# wsoc_mmu_secure register map
Vendor: Texas Instruments
Peripheral module from a debugger description file (folder CC35X1E).
Registers are 32-bit, access per field, reset 0x0 unless marked. A register's access mark holds for its fields unless they carry their own. Offsets are as the file gives them; lines under a group give offsets from that group; [hi:lo] are bit positions; {n}, {i} and the like mark numbered series; 'fields as' and 'values as' point back to an identical list; <NAME> marks a mode.

## wsoc_mmu_secure
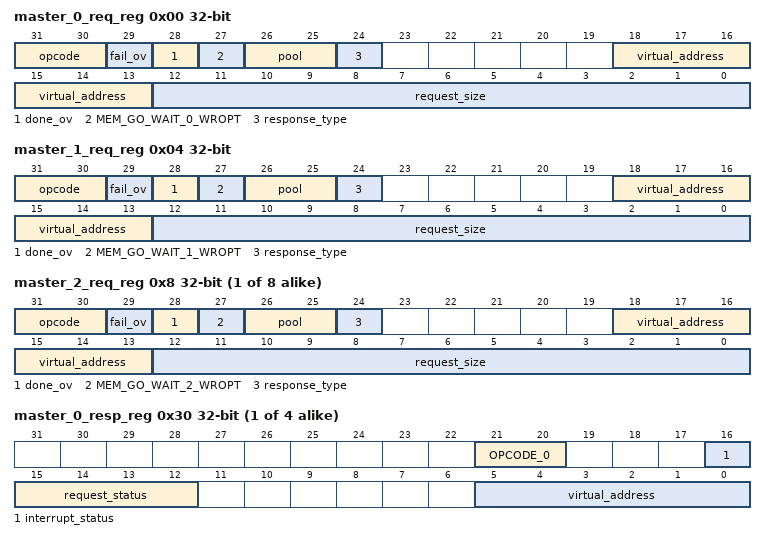
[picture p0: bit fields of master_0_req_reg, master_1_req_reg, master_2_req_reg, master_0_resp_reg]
0x00 master_0_req_reg reset not defined
  [31:30] opcode rw — Opcode : alloc (2'b00) / re-alloc (2'b01) / de-alloc (2'b10)
  [29] fail_ov rw — go to "no req" status instead of "error"
  [28] done_ov rw — go to "no req" status instead of "done"
  [27] MEM_GO_WAIT_0_WROPT rw — 1 = when fail on size or pool go to "wait" and not to "fail"/"no_req"
  [26:25] pool rw — Pool = TX (2'b00) / RX (2'b01) / management (2'b10)
  [24] response_type rw — 1 = response with interrupt
  [18:13] virtual_address rw — Virtual descriptor - should be shifted to the left to create the virtual address
  [12:0] request_size rw — Size (in Bytes) : 1-4096
0x04 master_1_req_reg reset not defined
  [31:30] opcode rw — Opcode : alloc (2'b00) / re-alloc (2'b01) / de-alloc (2'b10)
  [29] fail_ov rw — go to "no req" status instead of "error"
  [28] done_ov rw — go to "no req" status instead of "done"
  [27] MEM_GO_WAIT_1_WROPT rw — 1 = when fail on size or pool go to "wait" and not to "fail"/"no_req"
  [26:25] pool rw — Pool = TX (2'b00) / RX (2'b01) / management (2'b10)
  [24] response_type rw — 1 = response with interrupt
  [18:13] virtual_address rw — Virtual descriptor - should be shifted left to create the virtual address
  [12:0] request_size rw — Size (in Bytes) : 1-4096
{0x0+4i} master_{i}_req_reg reset not defined (i=2..9)
  [31:30] opcode rw — Opcode : alloc (2'b00) / re-alloc (2'b01) / de-alloc (2'b10)
  [29] fail_ov rw — go to "no req" status instead of "error"
  [28] done_ov rw — go to "no req" status instead of "done"
  [27] MEM_GO_WAIT_{i}_WROPT rw — 1 = when fail on size or pool go to "wait" and not to "fail"/"no_req"
  [26:25] pool rw — Pool = TX (2'b00) / RX (2'b01) / management (2'b10)
  [24] response_type rw — 1 = response with interrupt
  [18:13] virtual_address rw — Virtual descriptor - should be shifted left to create virtual address
  [12:0] request_size rw — Size (in Bytes) : 1-4096
{0x30+4i} master_{i}_resp_reg ro (i=0..3)
  [21:20] OPCODE_{i} — request opcode - updated when in "wait" status
  [16] interrupt_status — when "1" indicates that finished one iteration on the FSM and is in sticky mode
  [15:12] request_status — 4'b0000 = NO_REQ 4'b0010 = WAIT 4'b0001 = IN_PROGRESS 4'b1000 = SUCCESS 4'b1001 = FAIL_NF_DESC // NF = No Free 4'b1010 = FAIL_NF_MB // NF = No Free 4'b1011 = FAIL_SW 4'b1111 = ERROR
  [5:0] virtual_address — virtual descriptor
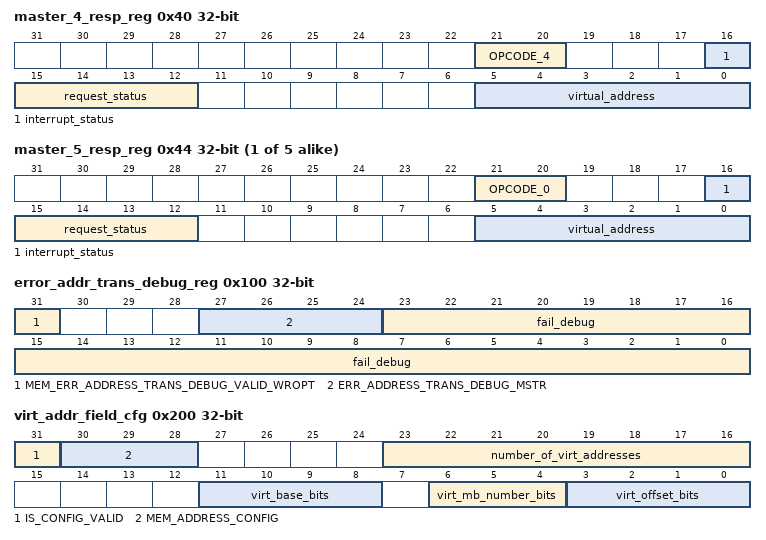
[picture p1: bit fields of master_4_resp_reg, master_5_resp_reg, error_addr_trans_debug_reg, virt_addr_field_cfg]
0x40 master_4_resp_reg ro
  [21:20] OPCODE_4 — request opcode - updated when in "wait" status
  [16] interrupt_status — when "1" indicates that finished one iteration on the FSM and is in sticky mode
  [15:12] request_status — 4'b0000 = NO_REQ 4'b0010 = WAIT 4'b0001 = IN_PROGRESS 4'b1000 = SUCCESS 4'b1001 = FAIL_NF_DESC // NF = No Free 4'b1010 = FAIL_NF_MB // NF = No Free 4'b1011 = FAIL_SW 4'b1111 = ERROR
  [5:0] virtual_address — virtual desriptor
{0x30+4i} master_{i}_resp_reg ro (i=5..9)
  fields as master_0_resp_reg
0x58 de_alloc_fifo_manager_cfg reset not defined
  [0] MEM_DEALLOC_FIFO_MANAGER_EN_WROPT rw — enables the dealloc fifo manager. when set to "1" it set to "1" shadow register, which will update the real register when fifo manager isn't during operation.
0x100 error_addr_trans_debug_reg reset not defined
  [31] MEM_ERR_ADDRESS_TRANS_DEBUG_VALID_WROPT rw — valid bit, when 1 the data is valid, and can't be written by the HW till FW clears it.
  [27:24] ERR_ADDRESS_TRANS_DEBUG_MSTR ro — The master id that triggered the address translation interrupt.
  [23:0] fail_debug ro — The address that triggered the address translation interrupt.
0x200 virt_addr_field_cfg reset not defined
  [31] IS_CONFIG_VALID ro — valid if MEM_ADDRESS_CONFIG is in range 0..7 (2 and 5 are not supporterd - 128B MMBLK mode) ADDR_CFG_0 : is_config_valid = 1'b1; ADDR_CFG_1 : is_config_valid = 1'b1; ADDR_CFG_2 : is_config_valid = 1'b0; //128B is not supported in Osprey ADDR_CFG_3 : is_config_valid = 1'b1; ADDR_CFG_4 : is_config_valid = 1'b1; ADDR_CFG_5 : is_config_valid = 1'b0; //128B is not supported in Osprey ADDR_CFG_6 : is_config_valid = 1'b1; ADDR_CFG_7 : is_config_valid = 1'b1;
  [30:28] MEM_ADDRESS_CONFIG rw — the configurations need to be correlated to the other fields - virt_offset_bits, virt_mb_number_bits and virt_base_bits config = 0 : 128 virt desc, 8 mb (max in each virt desc), 512B (each mb size) -> 4KB virtual space config = 1 : 128 virt desc, 16 mb (max in each virt desc), 256B (each mb size) -> 4KB virtual space config = 2 : 128 virt desc, 32 mb (max in each virt desc), 128B (each mb size) -> 4KB virtual space config = 3 : 256 desc, 4 mb (max in each virt desc), 512B (each mb size) -> 2KB virtual space config = 4 : 256 desc, 8 mb (max in each virt desc), 256B (each mb size) -> 2KB virtual space config =5 : 256 desc, 16 mb (max in each virt desc), 128B (each mb size) -> 2KB virtual space config = 6 : 128 virt desc, 16 mb (max in each virt desc), 512B (each mb size) -> 8KB virtual space config = 7 : 128 virt desc, 32 mb (max in each virt desc), 256B (each mb size) -> 8KB virtual space
  [23:16] number_of_virt_addresses rw — number of virtual descriptors - should be also synced with the tail pointers this value is used in the init fsm MUST BE EVEN NUMBER. odd value will fail the HW.
  [11:8] virt_base_bits ro — size in bits of virtual base field: mem_virt_base_bits[3:0] == 7, can represent 128 virt desc -> for configurations 0,1,2 mem_virt_base_bits[3:0] == 8, can represent 256 virt desc -> for configurations 3,4,5
  [6:4] virt_mb_number_bits ro — size in bits of virtual memblock number field: mem_virt_mb_number_bits[2:0] == 3'h2, can represent 4 mb -> for configuration 3 mem_virt_mb_number_bits[2:0] == 3'h3, can represent 8 mb -> for configurations 0,4 mem_virt_mb_number_bits[2:0] == 3'h4, can represent 16 mb -> for configurations 1,5 mem_virt_mb_number_bits[2:0] == 3'h5, can represent 32 mb -> for configuration 2
  [3:0] virt_offset_bits ro — size in bits of virtual offset field: mem_virt_offset_bits[3:0] == 4'h9, can represent 512B in the mb -> for configurations 0,3 mem_virt_offset_bits[3:0] == 4'h8, can represent 256B in the mb -> for configurations 1,4 mem_virt_offset_bits[3:0] == 4'h7, can represent 128B in the mb -> for configurations 2,5
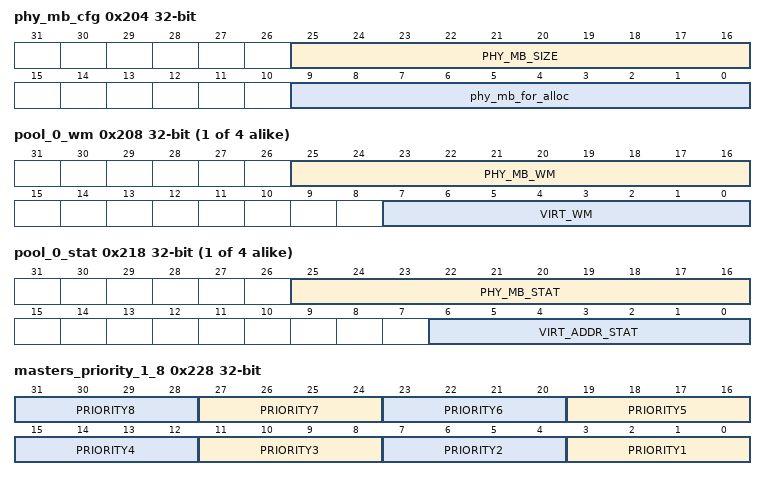
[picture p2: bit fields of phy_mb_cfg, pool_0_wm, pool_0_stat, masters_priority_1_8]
0x204 phy_mb_cfg reset not defined
  [25:16] PHY_MB_SIZE rw — physical memblock size, should be one of these options: 128, 256, 512 (the design supports 2^... format)
  [9:0] phy_mb_for_alloc rw — number of physical memblocks for allocation. should be synced with the tail pointers. this value is used in the init fsm. MUST BE EVEN NUMBER. odd value will fail the HW.
{0x208+4i} pool_{i}_wm reset not defined (i=0..3)
  [25:16] PHY_MB_WM rw — physical mb pool limit can be water mark or statistics. if water mark mechanism is enabled, when the number of virtual used (allocated) is higher than this value, this pool will fail to allocate. if statistics (stat) mechanism is enabled, when the number of virtual used (allocated) in this pool higher than this value, this pool will fail to allocate.
  [7:0] VIRT_WM rw — virtual desc pool limit can be water mark or statistics. if water mark mechanism is enabled, when the number of virtual used (allocated) is higher than this value, this pool will fail to allocate. if statistics (stat) mechanism is enabled, when the number of virtual used (allocated) in this pool higher than this value, this pool will fail to allocate.
{0x218+4i} pool_{i}_stat (i=0..3)
  [25:16] PHY_MB_STAT rw — physical memblocks statistics - how many memblocks allocated in this pool
  [6:0] VIRT_ADDR_STAT rw — virtual address statistics - how many virtual descriptors allocated in this pool
0x228 masters_priority_1_8 rw reset not defined
  [4n-1:4n-4] PRIORITY{n} (n=1..8) — master id assigned to priority {n}
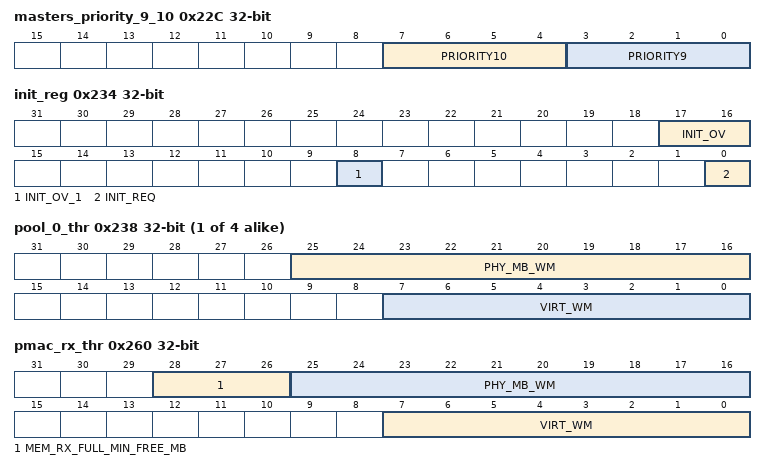
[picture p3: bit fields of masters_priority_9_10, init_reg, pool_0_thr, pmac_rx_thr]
0x22C masters_priority_9_10 reset not defined
  [7:4] PRIORITY10 rw — master id assigned to priority 10
  [3:0] PRIORITY9 rw — master id assigned to priority 9
0x230 fsms_arb_priority reset not defined
  [0] MEM_MNG_FSM rw — "0" for Address Translation FSM, "1" for Memory Management FSM
0x234 init_reg reset not defined
  [17:16] INIT_OV ro — init state 00 - INIT_IDLE 01 - INIT_RUN 10 - INIT_DONE
  [8] INIT_OV_1 ro — constant register configuration from top AOD select if MMU will run INIT after reset 0 = run INIT after reset 1 = do NOT run init
  [0] INIT_REQ rw — command to start init of MMU memories
{0x238+4i} pool_{i}_thr reset not defined (i=0..3)
  [25:16] PHY_MB_WM rw — threshold value for allocated physical memblocks. in pool water mark mechanism, when mb used number is going under this value, an interrupt will be triggered if isn't masked. in pool statistics mechanism, when this pool allocated mb number is going under this avlue, an interrupt will be triggered if not masked.
  [7:0] VIRT_WM rw — threshold value for allocated virtual descriptors. in pool water mark mechanism, when virt used descriptors number is going under this value, an interrupt will be triggered if isn't masked. in pool statistics mechanism, when this pool allocated virt descriptors number is going under this avlue, an interrupt will be triggered if not masked.
0x260 pmac_rx_thr reset not defined
  [28:26] MEM_RX_FULL_MIN_FREE_MB rw — impact rx_full indication number of free MB needed BELOW the minimum threshold between WM (mem_pool_phy_mb_wm_1) and PHY (mem_phy_mb_for_alloc) needed in order to avoid init-alloc-requests (of size > 1) that will fail because free_mb is less than requested_mb
  [25:16] PHY_MB_WM rw — threshold value for allocated physical memblocks. used by pmac_rx_adu as mmu-almost-full when MEM_POOL_STAT_MECH = 0 (pool WaterMark): set when mb_used is above this threshold value when MEM_POOL_STAT_MECH = 1 (pool Statistics): set when pool_phy_mb_addr_stat_1(rx pool) is above this threshold value
  [7:0] VIRT_WM rw — threshold value for allocated virtual descriptors. used by pmac_rx_adu as mmu-almost-full when MEM_POOL_STAT_MECH = 0 (pool WaterMark): set when virt_used is above this threshold value when MEM_POOL_STAT_MECH = 1 (pool Statistics): set when pool_virt_addr_stat_1(rx pool) is above this threshold value
0x270 message_buffer_config_1 reset not defined
  [17:0] MEM_MSG_BUF_START_ADDR rw — message_buffer start-address - OCP offset from PRAM BASE address represents the actual OCP maddr[17:0] of PRAM 16 MSBs [17:2] are used as start pointer to RAM. 2 LSBs [1:0] are dropped and assumed to be 2'b00
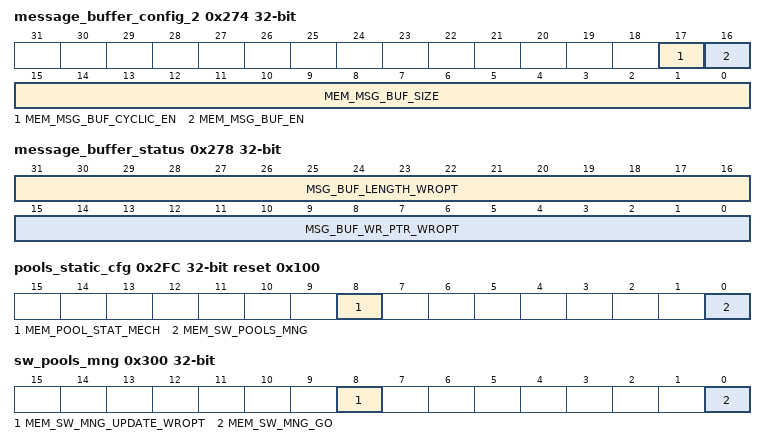
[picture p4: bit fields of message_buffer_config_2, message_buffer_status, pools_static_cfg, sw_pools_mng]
0x274 message_buffer_config_2 reset not defined
  [17] MEM_MSG_BUF_CYCLIC_EN rw — 0 - stop write to buffer when buffer is full (no message overwrite) 1 - cyclic-mode - continue write to buffer when it is full. write-pointer will wrap to start-address and continue write (overwrite old messages)
  [16] MEM_MSG_BUF_EN rw — 0 - message-buffer is disabled. OCP will continue to work normally but interface to PRAM will be disabled. freeze current status: wr_ptr and len keep their value. 1 - message-buffer is anabled. OCP write will be converted to PRAM write at rise - initialize counter and pointer to 0 (rise=init/restart)
  [15:0] MEM_MSG_BUF_SIZE rw — defines the number of words allocated to the message-buffer
0x278 message_buffer_status rw reset not defined
  [31:16] MSG_BUF_LENGTH_WROPT — Number of words written to message-buffer. Max value is mem_msg_buf_size.
  [15:0] MSG_BUF_WR_PTR_WROPT — write-pointer in words (increments by 1), points to the next empty address. Initial value is mem_msg_buf_start_addr[17:2] (OCP address divide by 4). Last message was written to (msg_buf_wr_ptr-1) When dumping the buffer content, need to start read from: (msg_buf_wr_ptr-msg_buf_length)*4 and consider cyclic address wrap. Also need to add PRAM base-address as ocp_maddr[23:18] Dumping the buffer content is done using direct PRAM access read from base 0xD0_0000 + offset of mem_msg_buf_start_addr[17:0]
0x2FC pools_static_cfg reset 0x100
  [8] MEM_POOL_STAT_MECH rw — 0 = pool wm mechanism to decide if the requested size is ok. 1 = pool statistics mechanism to decide...
  [0] MEM_SW_POOLS_MNG rw — "1" - SW manage pools through SW_POOLS_MNG FSM state "0" - HW manage pools
0x300 sw_pools_mng reset not defined
  [8] MEM_SW_MNG_UPDATE_WROPT rw — "1" - the SW_MNG_GO bit is valid. "0" - the SW_MNG_GO bit isn't valid. after SW turns this bit to valid, HW will use the SW_MNG_GO bit and clear this (the UPDATE) bit.
  [0] MEM_SW_MNG_GO rw — "1" - SW approves to continue in memory management FSM "0" - SW doesn't approve to continue in memory management FSM, will cause "fail" status to the relevant master and FSM will go back to IDLE
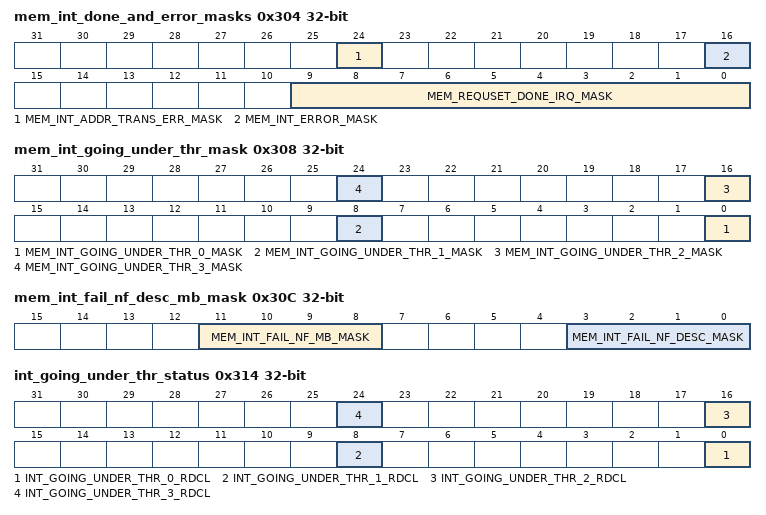
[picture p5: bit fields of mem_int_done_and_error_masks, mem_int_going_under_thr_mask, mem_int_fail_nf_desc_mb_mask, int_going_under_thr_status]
0x304 mem_int_done_and_error_masks reset not defined
  [24] MEM_INT_ADDR_TRANS_ERR_MASK rw — mask for error interrupt in address translation FSM (cortex only)
  [16] MEM_INT_ERROR_MASK rw — mask for error interrupt in memory management FSM (cortex only)
  [9:0] MEM_REQUSET_DONE_IRQ_MASK rw — mask for done interrupts, per master (0-9) - memory management FSM
0x308 mem_int_going_under_thr_mask reset not defined — masks for interrupts
  [8n] MEM_INT_GOING_UNDER_THR_{n}_MASK rw (n=0..3) — mask for going under threshold in pool X
0x30C mem_int_fail_nf_desc_mb_mask reset not defined — masks for interrupts
  [11:8] MEM_INT_FAIL_NF_MB_MASK rw — mask for fail because no free memblocks in pool X (X=0..3)
  [3:0] MEM_INT_FAIL_NF_DESC_MASK rw — mask for fail because no free descriptors in pool X (X=0..3)
0x314 int_going_under_thr_status ro
  [8n] INT_GOING_UNDER_THR_{n}_RDCL (n=0..3) — status of going under threshold interrupt for pool X. clear on read.
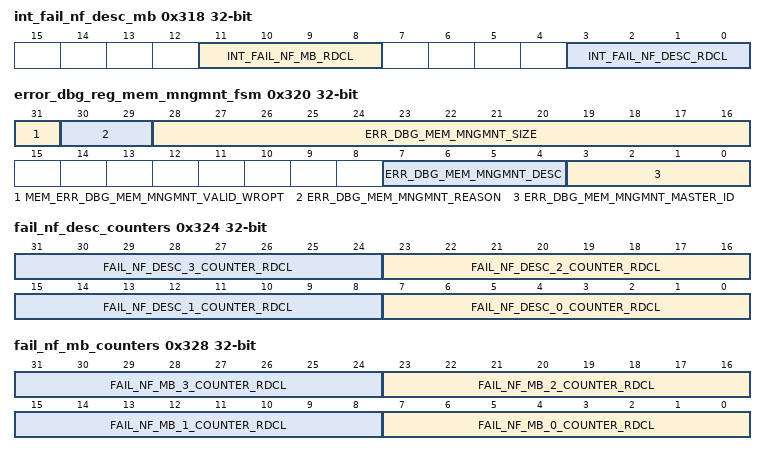
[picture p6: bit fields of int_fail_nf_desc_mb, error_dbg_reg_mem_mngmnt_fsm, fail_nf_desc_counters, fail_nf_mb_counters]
0x318 int_fail_nf_desc_mb ro
  [11:8] INT_FAIL_NF_MB_RDCL — interrupt for no free memblocks in pool X (X=0..3) for the request generated it. clear on read.
  [3:0] INT_FAIL_NF_DESC_RDCL — interrupt for no free descriptors in pool X (X=0..3) for the request generated it. clear on read.
0x320 error_dbg_reg_mem_mngmnt_fsm reset not defined — memory management FSM error debug register. updated when error occurs (only the releavnt fields of the error! when updated, the valid bit set to "1", and the register is locked untill SW clears this bit, by writing it to "0".
  [31] MEM_ERR_DBG_MEM_MNGMNT_VALID_WROPT rw — when this bit is "0", the debug register can be written by HW (for debug pupose). after error occurs, the register field will be updated and this bit sets to "1". when "1", the register is locked, and can't be written by HW. SW can clear it by writing "0". and than the debug register is ready for action...
  [30:29] ERR_DBG_MEM_MNGMNT_REASON ro — 2'b00 = not allocated descriptor 2'b01 = illegal address (not in MMU valid address space) 2'b10 = illegal request size (more than 2KB or 4KB, depend on the configuration) 2'b11 = request when the response status isn't "no_req"
  [28:16] ERR_DBG_MEM_MNGMNT_SIZE ro — request size that caused the error
  [7:4] ERR_DBG_MEM_MNGMNT_DESC ro — virtual descriptor that caused the error
  [3:0] ERR_DBG_MEM_MNGMNT_MASTER_ID ro — master-id that caused the error: 0 - mcu 1 - mcu 2 - mcu 3 - mcu 4 - reserved 5 - reserved 6 - reserved 7 - PMAC RX (ADU) 8 - NAB 9 - internal (Dealloc FIFO) Note: MMU-master-id is not the same as OCP-IC-master-id
0x324 fail_nf_desc_counters ro — counters for fail on no free descriptors per pool. read clear registers.
  [8n+7:8n] FAIL_NF_DESC_{n}_COUNTER_RDCL (n=0..3) — counter for fail requests on no free descriptors per pool. when arriving highest value 8'hff - it is locked, till read. read clear.
0x328 fail_nf_mb_counters ro — counters for fail on no free memblocks per pool. read clear registers.
  [8n+7:8n] FAIL_NF_MB_{n}_COUNTER_RDCL (n=0..3) — counter for fail requests on no free memblocks per pool. when arriving highest value 8'hff - it is locked, till read. read clear.
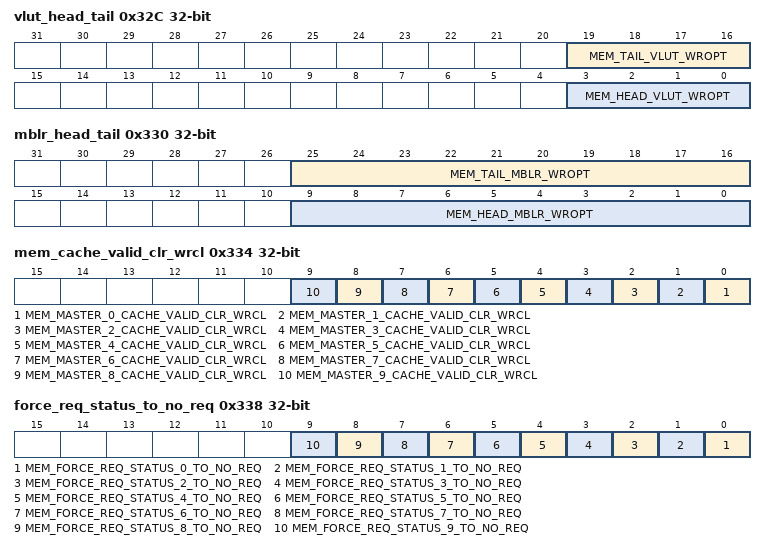
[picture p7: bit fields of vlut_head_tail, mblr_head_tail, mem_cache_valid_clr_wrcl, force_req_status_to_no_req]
0x32C vlut_head_tail reset not defined
  [19:16] MEM_TAIL_VLUT_WROPT rw — tail pointer for VLUT - should be synced with the amount of virt addresses at write - MUST BE ODD NUMBER. even value will fail the HW.
  [3:0] MEM_HEAD_VLUT_WROPT rw — head pointer for VLUT - should be 0 according to init mechanism
0x330 mblr_head_tail reset not defined
  [25:16] MEM_TAIL_MBLR_WROPT rw — tail pointer for MBLR - should be synced with the amount of phy mb to allocate at write - MUST BE ODD NUMBER. even value will fail the HW.
  [9:0] MEM_HEAD_MBLR_WROPT rw — head pointer for MBLR - should be 0 according to init mechanism
0x334 mem_cache_valid_clr_wrcl reset not defined — generates pulse that will reset the valid bit of the masters cache line.
  [n] MEM_MASTER_{n}_CACHE_VALID_CLR_WRCL wo (n=0..9)
0x338 force_req_status_to_no_req reset not defined — for use in extreme cases when need to switch response register from "steady wait" to "no_req". when set to "1", the response register status field is forced to "no_req". "steady wait" means "wait" that can't switched to "in progress". in order to bring the request register to steady wait, there is a need to set its priority to a number higher than 9. and read after the setting, if it is wait - it will be a steady wait. after using it - it should be written to "0", to enable regular operation.
  [n] MEM_FORCE_REQ_STATUS_{n}_TO_NO_REQ rw (n=0..9)
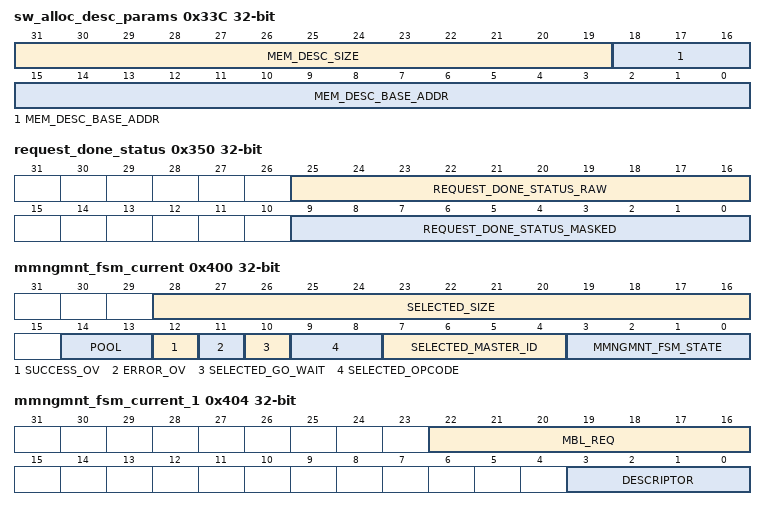
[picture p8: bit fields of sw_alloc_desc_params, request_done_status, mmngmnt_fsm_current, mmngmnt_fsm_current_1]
0x33C sw_alloc_desc_params rw reset not defined — registers for parsing SW allocated descriptors to actual PRAM address: Desc address = (Desc ID < mem_number_of_virt_addresses) ? regular address translation : (Desc ID - mem_number_of_virt_addresses+1)*DESC_SIZE
  [31:19] MEM_DESC_SIZE — the size of each SW allocated descriptor in bytes can be up to 512B TWO LSBs MUST BE 0 (size must be in multiples of 4)
  [18:0] MEM_DESC_BASE_ADDR — the actual PRAM address which the SW allocated descriptors start.
0x340 desc_limit reset not defined
  [8:0] MEM_DESC_LIMIT rw — limit to descriptor written in the address translation path (should include regular and sw allocated)
0x350 request_done_status ro reset not defined
  [25:16] REQUEST_DONE_STATUS_RAW — request done status - BEFORE MASK
  [9:0] REQUEST_DONE_STATUS_MASKED
0x400 mmngmnt_fsm_current ro
  [28:16] SELECTED_SIZE
  [14:13] POOL — Pool = TX (2'b00) / RX (2'b01) / management (2'b10)
  [12] SUCCESS_OV
  [11] ERROR_OV
  [10] SELECTED_GO_WAIT
  [9:8] SELECTED_OPCODE — ALLOC = 2'b00, REALLOC = 2'b01, DEALLOC = 2'b10;
  [7:4] SELECTED_MASTER_ID
  [3:0] MMNGMNT_FSM_STATE — 4'h0 = IDLE 4'h1 = SW_POOLS_MNG 4'h2 = VIRT_ALLOC 4'h3 = REALLOC_START 4'h4 = VIRT_DEALLOC 4'h5 = MBL_ALLOC 4'h6 = MBL_EOL 4'h7 = FIND_LAST_IN_MBL 4'h8 = READ_HEAD_MBL 4'h9 = MBL_DEALLOC
0x404 mmngmnt_fsm_current_1 ro
  [22:16] MBL_REQ — indication on the amount of memblocks needed to be allocated - being updated during allocation / reallocation process
  [3:0] DESCRIPTOR
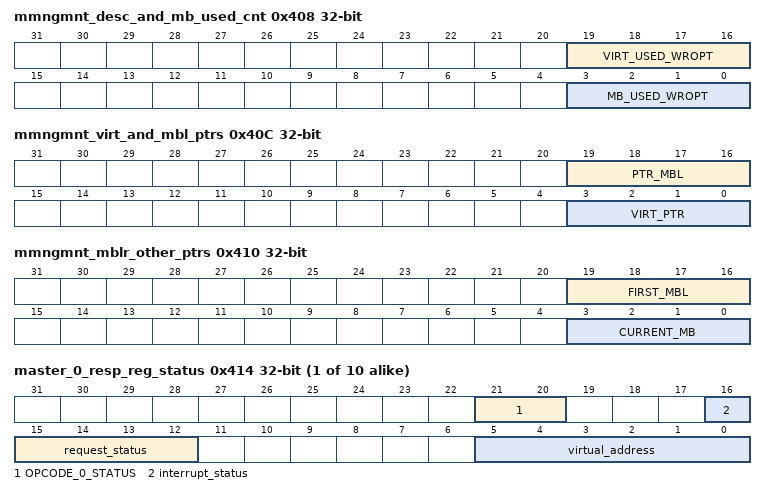
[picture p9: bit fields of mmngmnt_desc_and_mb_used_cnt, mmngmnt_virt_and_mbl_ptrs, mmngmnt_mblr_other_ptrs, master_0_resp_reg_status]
0x408 mmngmnt_desc_and_mb_used_cnt
  [19:16] VIRT_USED_WROPT rw — amount of allocated virtual descriptors - being updated during allocation / deallocation process
  [3:0] MB_USED_WROPT rw — amount of allocated memblocks - being updated during allocation / reallocation / deallocation process
0x40C mmngmnt_virt_and_mbl_ptrs ro
  [19:16] PTR_MBL — PTR MBL is the address on the MBL ram in few scenarios: assign MBLR_address[MBLR_LINES-1:0] = (mem_mngmnt_fsm_state[3:0] == VIRT_ALLOC) & (next_VLUT_changed | VLUT_changed) ? mem_head_mblr_wropt[MBLR_LINES-1:0] : (mem_mngmnt_fsm_state[3:0] == MBL_ALLOC) ? next_ptr_mbl[MBLR_LINES-1:0] : (mem_mngmnt_fsm_state[3:0] == MBL_EOL) & ~eol_updated ? ptr_mbl[MBLR_LINES-1:0] : (mem_mngmnt_fsm_state[3:0] == REALLOC_START) & (next_VLUT_changed | VLUT_changed) ? next_current_mb[MBLR_LINES-1:0] : (mem_mngmnt_fsm_state[3:0] == FIND_LAST_IN_MBL) & (next_ptr_mbl[MBLR_LINES:0] != EOL[MBLR_WIDTH-1:0]) ? next_current_mb[MBLR_LINES-1:0] : (mem_mngmnt_fsm_state[3:0] == FIND_LAST_IN_MBL) & (next_ptr_mbl[MBLR_LINES:0] == EOL[MBLR_WIDTH-1:0]) ? current_mb[MBLR_LINES-1:0] : (mem_mngmnt_fsm_state[3:0] == READ_HEAD_MBL) ? mem_head_mblr_wropt[MBLR_LINES-1:0] : (mem_mngmnt_fsm_state[3:0] == VIRT_DEALLOC) & (next_VLUT_changed | VLUT_changed) & (mem_tail_mblr_wropt[MBLR_LINES:0] != EOL[MBLR_WIDTH-1:0]) & ~tail_connected ? mem_tail_mblr_wropt[MBLR_LINES-1:0] : (mem_mngmnt_fsm_state[3:0] == VIRT_DEALLOC) & (next_VLUT_changed | VLUT_changed) & tail_connected ? first_mbl[MBLR_LINES-1:0] : (mem_mngmnt_fsm_state[3:0] == MBL_DEALLOC) & (next_ptr_mbl[MBLR_LINES:0] != EOL[MBLR_WIDTH-1:0]) ? next_current_mb[MBLR_LINES-1:0] : {MBLR_LINES{1'h0}};
  [3:0] VIRT_PTR — VLUT ptr is the address on the VLUT ram in few scenarios: assign VLUT_address[VLUT_LINES-1:0] = (mem_mngmnt_fsm_state[3:0] == VIRT_ALLOC) & ~VLUT_changed ? mem_head_vlut_wropt[VLUT_LINES-1:0] : (mem_mngmnt_fsm_state[3:0] == REALLOC_START) & ~VLUT_changed ? virt_ptr[VLUT_LINES-1:0] : ((mem_mngmnt_fsm_state[3:0] == VIRT_DEALLOC) & ~VLUT_changed & dealloc_phase_1) ? virt_ptr[VLUT_LINES-1:0] : ((mem_mngmnt_fsm_state[3:0] == VIRT_DEALLOC) & ~VLUT_changed & ~dealloc_phase_1) ? tail_virt_d[VLUT_LINES-1:0] : (mem_mngmnt_fsm_state[3:0] == MBL_EOL) & eol_updated ? virt_ptr[VLUT_LINES-1:0] : {VLUT_LINES{1'h0}};
0x410 mmngmnt_mblr_other_ptrs ro
  [19:16] FIRST_MBL, [3:0] CURRENT_MB
{0x414+4i} master_{i}_resp_reg_status ro (i=0..9) — This register is for reading / debugging the status and not for operational use!!!
  [21:20] OPCODE_{i}_STATUS — request opcode - updated when in "wait" status
  [16] interrupt_status — when "1" indicates that finished one iteration on the FSM and is in sticky mode
  [15:12] request_status — 4'b0000 = NO_REQ 4'b0010 = WAIT 4'b0001 = IN_PROGRESS 4'b1000 = SUCCESS 4'b1001 = FAIL_NF_DESC // NF = No Free 4'b1010 = FAIL_NF_MB // NF = No Free 4'b1011 = FAIL_SW 4'b1111 = ERROR
  [5:0] virtual_address — virtual descriptor
{0x500+4i} cache_ocp_master_0_{i} ro (i=0..3)
  [3:0] CACHE_OCP_MASTER_0_{i} — CACHE_WIDTH = VLUT_LINES + 5(amount of max MBs in virtual descriptor) +MBLR_LINES + 1(bit valid)
{0x50C+4i} cache_ocp_master_{i} ro (i=1..9)
  [3:0] CACHE_OCP_MASTER_{i} — CACHE_WIDTH = VLUT_LINES + 5(amount of max MBs in virtual descriptor) +MBLR_LINES + 1(bit valid)
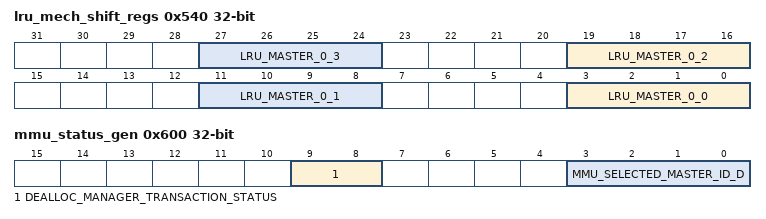
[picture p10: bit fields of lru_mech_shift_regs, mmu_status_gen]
0x540 lru_mech_shift_regs ro
  [8n+3:8n] LRU_MASTER_0_{n} (n=0..3) — 1 hot - if msb is "1", then this cahce line is the lru
0x544 master_0_least_used_d ro
  [1:0] MASTER_0_LEAST_USED_D — sampled!!! signal of the terminal least used cache line, when considering not allocated lines and the oldest theat was used.
0x600 mmu_status_gen ro
  [9:8] DEALLOC_MANAGER_TRANSACTION_STATUS, [3:0] MMU_SELECTED_MASTER_ID_D
0x1000 mem_vlut_ram — VLUT - contains 2 VLUT words, each 14 bits: when address is even -> [15:2] when address is odd -> [29:16]
  [29:2] MEM_VLUT_11FC_WRMEM rw
0x4000 mem_mbl_ram — MBLR - contains 2 MBLR words, each 10 bits: when address is even -> [15:6] when address is odd -> [25:16]
  [25:6] MEM_MBLR_4FFC_WRMEMP rw
